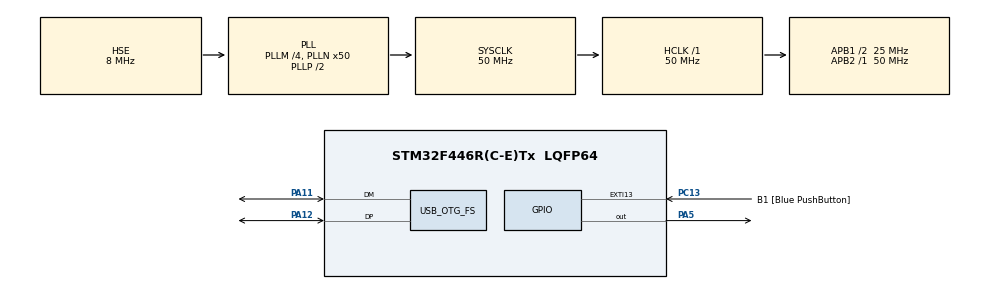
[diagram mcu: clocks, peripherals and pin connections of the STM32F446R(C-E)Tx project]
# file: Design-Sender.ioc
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Dma.Request0=TIM2_UP/CH3
Dma.TIM2_UP/CH3.0.Direction=DMA_MEMORY_TO_PERIPH
Dma.TIM2_UP/CH3.0.FIFOMode=DMA_FIFOMODE_DISABLE
Dma.TIM2_UP/CH3.0.Instance=DMA1_Stream1
Dma.TIM2_UP/CH3.0.MemDataAlignment=DMA_MDATAALIGN_WORD
Dma.TIM2_UP/CH3.0.MemInc=DMA_MINC_ENABLE
Dma.TIM2_UP/CH3.0.Mode=DMA_NORMAL
Dma.TIM2_UP/CH3.0.PeriphDataAlignment=DMA_PDATAALIGN_WORD
Dma.TIM2_UP/CH3.0.PeriphInc=DMA_PINC_DISABLE
Dma.TIM2_UP/CH3.0.Priority=DMA_PRIORITY_HIGH
Mcu.Family=STM32F4
Mcu.Name=STM32F446R(C-E)Tx
Mcu.Package=LQFP64
NVIC.DMA1_Stream1_IRQn=true\:0\:0\:false\:false\:true\:false\:true\:true
NVIC.PriorityGroup=NVIC_PRIORITYGROUP_0
PA11.Mode=Host_Only
PA11.Signal=USB_OTG_FS_DM
PA12.Mode=Host_Only
PA12.Signal=USB_OTG_FS_DP
PA13.GPIO_Label=TMS
PA13.Mode=Serial_Wire
PA13.Signal=SYS_JTMS-SWDIO
PA14.GPIO_Label=TCK
PA14.Mode=Serial_Wire
PA14.Signal=SYS_JTCK-SWCLK
PA2.GPIO_Label=USART_TX
PA2.Signal=USART2_TX
PA3.GPIO_Label=USART_RX
PA3.Signal=USART2_RX
PA5.GPIO_Speed=GPIO_SPEED_FREQ_VERY_HIGH
PA5.Signal=GPIO_Output
PB3.GPIO_Label=SWO
PB3.Signal=SYS_JTDO-SWO
PC13.GPIO_Label=B1 [Blue PushButton]
PC13.GPIO_ModeDefaultEXTI=GPIO_MODE_IT_FALLING
PC13.Signal=GPXTI13
PC14-OSC32_IN.Mode=LSE-External-Oscillator
PC14-OSC32_IN.Signal=RCC_OSC32_IN
PC15-OSC32_OUT.Mode=LSE-External-Oscillator
PC15-OSC32_OUT.Signal=RCC_OSC32_OUT
PH0-OSC_IN.Mode=HSE-External-Oscillator
PH0-OSC_IN.Signal=RCC_OSC_IN
PH1-OSC_OUT.Mode=HSE-External-Oscillator
PH1-OSC_OUT.Signal=RCC_OSC_OUT
ProjectManager.HeapSize=0x200
ProjectManager.StackSize=0x400
ProjectManager.TargetToolchain=STM32CubeIDE
RCC.48MHZClocksFreq_Value=84000000
RCC.AHBFreq_Value=50000000
RCC.APB1CLKDivider=RCC_HCLK_DIV2
RCC.APB1Freq_Value=25000000
RCC.APB1TimFreq_Value=50000000
RCC.APB2Freq_Value=50000000
RCC.APB2TimFreq_Value=50000000
RCC.CortexFreq_Value=50000000
RCC.FLatency-AdvancedSettings=FLASH_LATENCY_1
RCC.HCLKFreq_Value=50000000
RCC.HSE_VALUE=8000000
RCC.HSI_VALUE=16000000
RCC.PLLM=4
RCC.PLLN=50
RCC.PLLQ=5
RCC.PLLSAIM=4
RCC.PLLSAIN=96
RCC.PLLSAIP=RCC_PLLSAIP_DIV4
RCC.SYSCLKFreq_VALUE=50000000
RCC.SYSCLKSource=RCC_SYSCLKSOURCE_PLLCLK
RCC.USBCLockSelection=RCC_CLK48CLKSOURCE_PLLSAIP
RCC.USBFreq_Value=48000000
RCC.VCOOutputFreq_Value=100000000
TIM2.Period=9
TIM2.Prescaler=20
USB_OTG_FS.VirtualMode=Host_Only
USB_OTG_FS.phy_itface=HCD_PHY_EMBEDDED
VP_TIM2_VS_ClockSourceINT.Mode=Internal
board=NUCLEO-F446RE

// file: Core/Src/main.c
/* USER CODE BEGIN Header */
/**
  ******************************************************************************
  * @file           : main.c
  * @brief          : Main program body
  ******************************************************************************
  * @attention
  *
  * Copyright (c) 2025 STMicroelectronics.
  * All rights reserved.
  *
  * This software is licensed under terms that can be found in the LICENSE file
  * in the root directory of this software component.
  * If no LICENSE file comes with this software, it is provided AS-IS.
  *
  ******************************************************************************
  */
/* USER CODE END Header */
#include "main.h"
TIM_HandleTypeDef htim2;
DMA_HandleTypeDef hdma_tim2_up_ch3;
HCD_HandleTypeDef hhcd_USB_OTG_FS;

void SystemClock_Config(void);
static void MX_GPIO_Init(void);
static void MX_DMA_Init(void);
static void MX_TIM2_Init(void);
static void MX_USB_OTG_FS_HCD_Init(void);

int main(void)
{

  /* MCU Configuration--------------------------------------------------------*/

  /* Reset of all peripherals, Initializes the Flash interface and the Systick. */
  HAL_Init();

  /* Configure the system clock */
  SystemClock_Config();

  /* Initialize all configured peripherals */
  MX_GPIO_Init();
  MX_DMA_Init();
  MX_TIM2_Init();
  MX_USB_OTG_FS_HCD_Init();
  /* USER CODE BEGIN 2 */
  HAL_GPIO_WritePin(GPIOA, GPIO_PIN_5, GPIO_PIN_RESET);

  tusb_rhport_init_t host_init = { .role = TUSB_ROLE_HOST, .speed = TUSB_SPEED_FULL };
  tusb_init(0, &host_init);

  /* USER CODE END 2 */

  /* Infinite loop */
  while (1)
  {

  }
}

void SystemClock_Config(void)
{
  RCC_OscInitTypeDef RCC_OscInitStruct = {0};
  RCC_ClkInitTypeDef RCC_ClkInitStruct = {0};

  /** Configure the main internal regulator output voltage
  */
  __HAL_RCC_PWR_CLK_ENABLE();
  __HAL_PWR_VOLTAGESCALING_CONFIG(PWR_REGULATOR_VOLTAGE_SCALE3);

  /** Initializes the RCC Oscillators according to the specified parameters
  * in the RCC_OscInitTypeDef structure.
  */
  RCC_OscInitStruct.OscillatorType = RCC_OSCILLATORTYPE_HSE;
  RCC_OscInitStruct.HSEState = RCC_HSE_ON;
  RCC_OscInitStruct.PLL.PLLState = RCC_PLL_ON;
  RCC_OscInitStruct.PLL.PLLSource = RCC_PLLSOURCE_HSE;
  RCC_OscInitStruct.PLL.PLLM = 4;
  RCC_OscInitStruct.PLL.PLLN = 50;
  RCC_OscInitStruct.PLL.PLLP = RCC_PLLP_DIV2;
  RCC_OscInitStruct.PLL.PLLQ = 5;
  RCC_OscInitStruct.PLL.PLLR = 2;
  if (HAL_RCC_OscConfig(&RCC_OscInitStruct) != HAL_OK)
  {
    Error_Handler();
  }

  /** Initializes the CPU, AHB and APB buses clocks
  */
  RCC_ClkInitStruct.ClockType = RCC_CLOCKTYPE_HCLK|RCC_CLOCKTYPE_SYSCLK
                              |RCC_CLOCKTYPE_PCLK1|RCC_CLOCKTYPE_PCLK2;
  RCC_ClkInitStruct.SYSCLKSource = RCC_SYSCLKSOURCE_PLLCLK;
  RCC_ClkInitStruct.AHBCLKDivider = RCC_SYSCLK_DIV1;
  RCC_ClkInitStruct.APB1CLKDivider = RCC_HCLK_DIV2;
  RCC_ClkInitStruct.APB2CLKDivider = RCC_HCLK_DIV1;

  if (HAL_RCC_ClockConfig(&RCC_ClkInitStruct, FLASH_LATENCY_1) != HAL_OK)
  {
    Error_Handler();
  }
}

static void MX_TIM2_Init(void)
{

  TIM_ClockConfigTypeDef sClockSourceConfig = {0};
  TIM_MasterConfigTypeDef sMasterConfig = {0};

  htim2.Instance = TIM2;
  htim2.Init.Prescaler = 20;
  htim2.Init.CounterMode = TIM_COUNTERMODE_UP;
  htim2.Init.Period = 9;
  htim2.Init.ClockDivision = TIM_CLOCKDIVISION_DIV1;
  htim2.Init.AutoReloadPreload = TIM_AUTORELOAD_PRELOAD_DISABLE;
  if (HAL_TIM_Base_Init(&htim2) != HAL_OK)
  {
    Error_Handler();
  }
  sClockSourceConfig.ClockSource = TIM_CLOCKSOURCE_INTERNAL;
  if (HAL_TIM_ConfigClockSource(&htim2, &sClockSourceConfig) != HAL_OK)
  {
    Error_Handler();
  }
  sMasterConfig.MasterOutputTrigger = TIM_TRGO_RESET;
  sMasterConfig.MasterSlaveMode = TIM_MASTERSLAVEMODE_DISABLE;
  if (HAL_TIMEx_MasterConfigSynchronization(&htim2, &sMasterConfig) != HAL_OK)
  {
    Error_Handler();
  }

}

static void MX_USB_OTG_FS_HCD_Init(void)
{

  hhcd_USB_OTG_FS.Instance = USB_OTG_FS;
  hhcd_USB_OTG_FS.Init.Host_channels = 12;
  hhcd_USB_OTG_FS.Init.speed = HCD_SPEED_FULL;
  hhcd_USB_OTG_FS.Init.dma_enable = DISABLE;
  hhcd_USB_OTG_FS.Init.phy_itface = HCD_PHY_EMBEDDED;
  hhcd_USB_OTG_FS.Init.Sof_enable = DISABLE;
  if (HAL_HCD_Init(&hhcd_USB_OTG_FS) != HAL_OK)
  {
    Error_Handler();
  }

}

static void MX_DMA_Init(void)
{

  /* DMA controller clock enable */
	__HAL_RCC_DMA1_CLK_ENABLE();

  /* DMA interrupt init */
  /* DMA1_Stream1_IRQn interrupt configuration */
  HAL_NVIC_SetPriority(DMA1_Stream1_IRQn, 0, 0);
  HAL_NVIC_EnableIRQ(DMA1_Stream1_IRQn);

}

static void MX_GPIO_Init(void)
{
  GPIO_InitTypeDef GPIO_InitStruct = {0};

  /* GPIO Ports Clock Enable */
  __HAL_RCC_GPIOC_CLK_ENABLE();
  __HAL_RCC_GPIOH_CLK_ENABLE();
  __HAL_RCC_GPIOA_CLK_ENABLE();
  __HAL_RCC_GPIOB_CLK_ENABLE();

  /*Configure GPIO pin Output Level */
  HAL_GPIO_WritePin(GPIOA, GPIO_PIN_5, GPIO_PIN_RESET);

  /*Configure GPIO pin : B1_Pin */
  GPIO_InitStruct.Pin = B1_Pin;
  GPIO_InitStruct.Mode = GPIO_MODE_IT_FALLING;
  GPIO_InitStruct.Pull = GPIO_NOPULL;
  HAL_GPIO_Init(B1_GPIO_Port, &GPIO_InitStruct);

  /*Configure GPIO pins : USART_TX_Pin USART_RX_Pin */
  GPIO_InitStruct.Pin = USART_TX_Pin|USART_RX_Pin;
  GPIO_InitStruct.Mode = GPIO_MODE_AF_PP;
  GPIO_InitStruct.Pull = GPIO_NOPULL;
  GPIO_InitStruct.Speed = GPIO_SPEED_FREQ_VERY_HIGH;
  GPIO_InitStruct.Alternate = GPIO_AF7_USART2;
  HAL_GPIO_Init(GPIOA, &GPIO_InitStruct);

  /*Configure GPIO pin : PA5 */
  GPIO_InitStruct.Pin = GPIO_PIN_5;
  GPIO_InitStruct.Mode = GPIO_MODE_OUTPUT_PP;
  GPIO_InitStruct.Pull = GPIO_NOPULL;
  GPIO_InitStruct.Speed = GPIO_SPEED_FREQ_VERY_HIGH;
  HAL_GPIO_Init(GPIOA, &GPIO_InitStruct);

}

void Error_Handler(void)
{
  __disable_irq();
  while (1)
  {
  }
}

uint32_t tusb_time_millis_api(void) {
  return HAL_GetTick();   // HAL tick is 1 ms if SysTick is running
}
